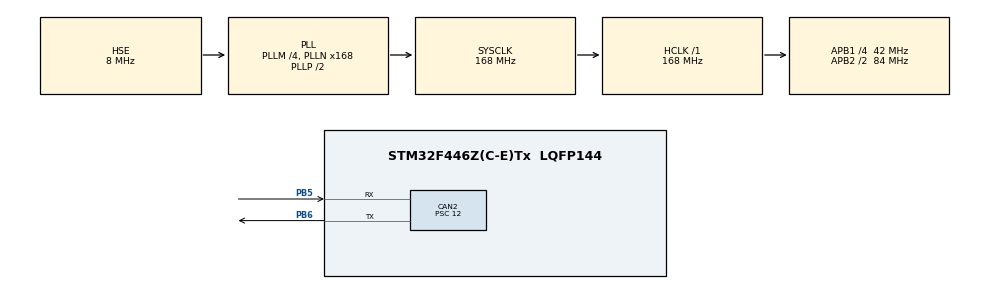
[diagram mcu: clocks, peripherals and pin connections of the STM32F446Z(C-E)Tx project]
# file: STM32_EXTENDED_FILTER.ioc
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CAN2.BS1=CAN_BS1_6TQ
CAN2.BS2=CAN_BS2_7TQ
CAN2.CalculateBaudRate=250000
CAN2.CalculateTimeBit=4000
CAN2.CalculateTimeQuantum=285.7142857142857
CAN2.Prescaler=12
Mcu.Family=STM32F4
Mcu.Name=STM32F446Z(C-E)Tx
Mcu.Package=LQFP144
NVIC.PriorityGroup=NVIC_PRIORITYGROUP_4
PA13.Mode=Serial_Wire
PA13.Signal=SYS_JTMS-SWDIO
PA14.Mode=Serial_Wire
PA14.Signal=SYS_JTCK-SWCLK
PB5.Mode=CAN_Activate
PB5.Signal=CAN2_RX
PB6.Mode=CAN_Activate
PB6.Signal=CAN2_TX
PH0-OSC_IN.Mode=HSE-External-Oscillator
PH0-OSC_IN.Signal=RCC_OSC_IN
PH1-OSC_OUT.Mode=HSE-External-Oscillator
PH1-OSC_OUT.Signal=RCC_OSC_OUT
ProjectManager.HeapSize=0x200
ProjectManager.StackSize=0x400
ProjectManager.TargetToolchain=STM32CubeIDE
RCC.AHBFreq_Value=168000000
RCC.APB1CLKDivider=RCC_HCLK_DIV4
RCC.APB1Freq_Value=42000000
RCC.APB1TimFreq_Value=84000000
RCC.APB2CLKDivider=RCC_HCLK_DIV2
RCC.APB2Freq_Value=84000000
RCC.APB2TimFreq_Value=168000000
RCC.CortexFreq_Value=168000000
RCC.HCLKFreq_Value=168000000
RCC.HSE_VALUE=8000000
RCC.PLLM=4
RCC.PLLN=168
RCC.PLLSourceVirtual=RCC_PLLSOURCE_HSE
RCC.SYSCLKFreq_VALUE=168000000
RCC.SYSCLKSource=RCC_SYSCLKSOURCE_PLLCLK
RCC.USBFreq_Value=168000000
RCC.VCOOutputFreq_Value=336000000
board=custom

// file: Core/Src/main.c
/* USER CODE BEGIN Header */
/**
  ******************************************************************************
  * @file           : main.c
  * @brief          : Main program body
  ******************************************************************************
  * @attention
  *
  * Copyright (c) 2024 STMicroelectronics.
  * All rights reserved.
  *
  * This software is licensed under terms that can be found in the LICENSE file
  * in the root directory of this software component.
  * If no LICENSE file comes with this software, it is provided AS-IS.
  *
  ******************************************************************************
  */
/* USER CODE END Header */
#include "main.h"

/* USER CODE BEGIN Includes */
#define  CAN_IDE_32 0b00000100 // bu ıde bitini ekleme sebebimiz bazı durumlarda hem stdr ıd icin hem extdıd icin calıacaktır bunu engellemek ıcın tanımlıyoruz

/* USER CODE END Includes */

CAN_HandleTypeDef hcan2;

void SystemClock_Config(void);
static void MX_GPIO_Init(void);
static void MX_CAN2_Init(void);

/* USER CODE BEGIN 0 */

CAN_TxHeaderTypeDef Gonderilen_veri;
CAN_RxHeaderTypeDef Alinan_veri;
CAN_FilterTypeDef exFilterconfig;

uint8_t count[8]; //gönderilecek değer

uint8_t rcount[8]; //alinacak değer
uint32_t bilgi[5]; //alim işlemi sirasinda bizden istenen mailbax
uint32_t gbilgi;

/* USER CODE END 0 */

int main(void)
{

  /* MCU Configuration--------------------------------------------------------*/

  /* Reset of all peripherals, Initializes the Flash interface and the Systick. */
  HAL_Init();

  /* Configure the system clock */
  SystemClock_Config();

  /* Initialize all configured peripherals */
  MX_GPIO_Init();
  MX_CAN2_Init();
  /* USER CODE BEGIN 2 */
  HAL_CAN_Start(&hcan2);

  Gonderilen_veri.DLC = 1; //gonderilecek mesaj kac bytelik?
  Gonderilen_veri.IDE = CAN_ID_EXT; // stn mi rxt mi göndereceksin
  Gonderilen_veri.RTR = CAN_RTR_DATA; // o sa mesaj geitrdim diyordu 1 se istek yapiyor
  Gonderilen_veri.ExtId = 0x1FBF9000; // 29 bitlik deger göndericez ve ıd degerimiz bu

  exFilterconfig.FilterActivation = CAN_FILTER_ENABLE; //fiter ative ediyoruz
  exFilterconfig.FilterBank = 0;
  exFilterconfig.FilterFIFOAssignment = CAN_FILTER_FIFO0; //ıd degerı 0x1FBF9000 0x1AB03000 ıse mesajı al
  exFilterconfig.FilterIdHigh = 0x1FBF9000 >> 13;
  exFilterconfig.FilterIdLow = 0x1FBF9000 | CAN_IDE_32 << 3;
  exFilterconfig.FilterMaskIdHigh = 0x1AB03000 >> 13;
  exFilterconfig.FilterMaskIdLow = 0x1AB03000 | CAN_IDE_32 << 3;
  exFilterconfig.FilterMode = CAN_FILTERMODE_IDLIST;
  exFilterconfig.FilterScale = CAN_FILTERSCALE_32BIT;

  HAL_CAN_ConfigFilter(&hcan2, &exFilterconfig);

  /* USER CODE END 2 */

  /* Infinite loop */
  while (1)
  {

    /* USER CODE BEGIN 3 */
	  //HAL_CAN_AddTxMessage(&hcan2, &Gonderilen_veri, &count, bilgi);

	  HAL_CAN_AddTxMessage(&hcan2, &Gonderilen_veri, count, &gbilgi);
	  //HAL_CAN_GetRxMessage(&hcan2, CAN_RX_FIFO0, &Alinan_veri, rcount);

	  bilgi[0] = Alinan_veri.DLC;
	  bilgi[1] = Alinan_veri.ExtId;
	  bilgi[2] = Alinan_veri.IDE; //ext id ise sonu 4 gelir
	  bilgi[3] = Alinan_veri.RTR; // Data frame ise sonu 0

  }
  /* USER CODE END 3 */
}

void SystemClock_Config(void)
{
  RCC_OscInitTypeDef RCC_OscInitStruct = {0};
  RCC_ClkInitTypeDef RCC_ClkInitStruct = {0};

  /** Configure the main internal regulator output voltage
  */
  __HAL_RCC_PWR_CLK_ENABLE();
  __HAL_PWR_VOLTAGESCALING_CONFIG(PWR_REGULATOR_VOLTAGE_SCALE1);

  /** Initializes the RCC Oscillators according to the specified parameters
  * in the RCC_OscInitTypeDef structure.
  */
  RCC_OscInitStruct.OscillatorType = RCC_OSCILLATORTYPE_HSE;
  RCC_OscInitStruct.HSEState = RCC_HSE_ON;
  RCC_OscInitStruct.PLL.PLLState = RCC_PLL_ON;
  RCC_OscInitStruct.PLL.PLLSource = RCC_PLLSOURCE_HSE;
  RCC_OscInitStruct.PLL.PLLM = 4;
  RCC_OscInitStruct.PLL.PLLN = 168;
  RCC_OscInitStruct.PLL.PLLP = RCC_PLLP_DIV2;
  RCC_OscInitStruct.PLL.PLLQ = 2;
  RCC_OscInitStruct.PLL.PLLR = 2;
  if (HAL_RCC_OscConfig(&RCC_OscInitStruct) != HAL_OK)
  {
    Error_Handler();
  }

  /** Initializes the CPU, AHB and APB buses clocks
  */
  RCC_ClkInitStruct.ClockType = RCC_CLOCKTYPE_HCLK|RCC_CLOCKTYPE_SYSCLK
                              |RCC_CLOCKTYPE_PCLK1|RCC_CLOCKTYPE_PCLK2;
  RCC_ClkInitStruct.SYSCLKSource = RCC_SYSCLKSOURCE_PLLCLK;
  RCC_ClkInitStruct.AHBCLKDivider = RCC_SYSCLK_DIV1;
  RCC_ClkInitStruct.APB1CLKDivider = RCC_HCLK_DIV4;
  RCC_ClkInitStruct.APB2CLKDivider = RCC_HCLK_DIV2;

  if (HAL_RCC_ClockConfig(&RCC_ClkInitStruct, FLASH_LATENCY_5) != HAL_OK)
  {
    Error_Handler();
  }
}

static void MX_CAN2_Init(void)
{

  hcan2.Instance = CAN2;
  hcan2.Init.Prescaler = 12;
  hcan2.Init.Mode = CAN_MODE_NORMAL;
  hcan2.Init.SyncJumpWidth = CAN_SJW_1TQ;
  hcan2.Init.TimeSeg1 = CAN_BS1_6TQ;
  hcan2.Init.TimeSeg2 = CAN_BS2_7TQ;
  hcan2.Init.TimeTriggeredMode = DISABLE;
  hcan2.Init.AutoBusOff = DISABLE;
  hcan2.Init.AutoWakeUp = DISABLE;
  hcan2.Init.AutoRetransmission = DISABLE;
  hcan2.Init.ReceiveFifoLocked = DISABLE;
  hcan2.Init.TransmitFifoPriority = DISABLE;
  if (HAL_CAN_Init(&hcan2) != HAL_OK)
  {
    Error_Handler();
  }

}

static void MX_GPIO_Init(void)
{

  /* GPIO Ports Clock Enable */
  __HAL_RCC_GPIOH_CLK_ENABLE();
  __HAL_RCC_GPIOA_CLK_ENABLE();
  __HAL_RCC_GPIOB_CLK_ENABLE();

}

void Error_Handler(void)
{
  __disable_irq();
  while (1)
  {
  }
}
